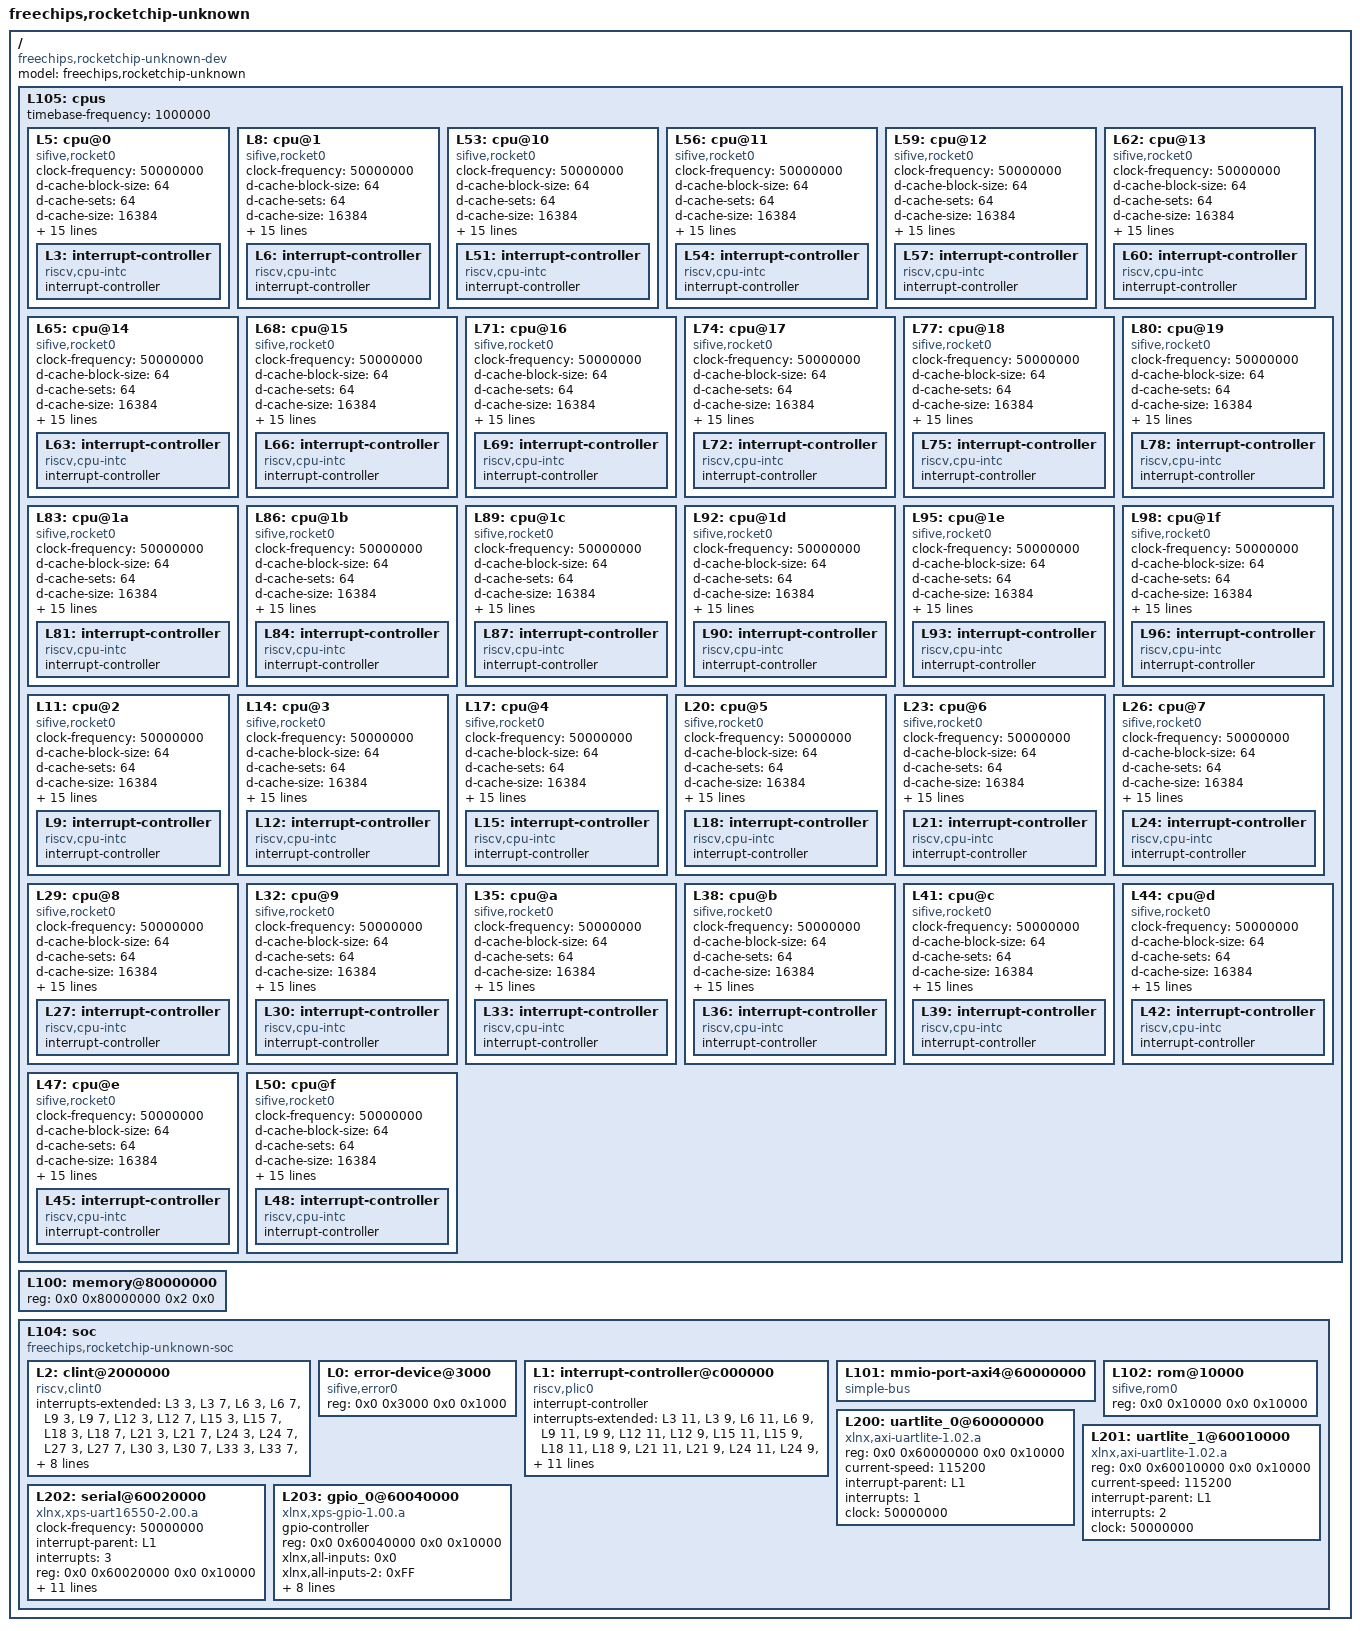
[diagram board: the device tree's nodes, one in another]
/dts-v1/;

/ {
	#address-cells = <2>;
	#size-cells = <2>;
	compatible = "freechips,rocketchip-unknown-dev";
	model = "freechips,rocketchip-unknown";
	L105: cpus {
		#address-cells = <1>;
		#size-cells = <0>;
        timebase-frequency = <1000000>;
		L5: cpu@0 {
			clock-frequency = <50000000>;
			compatible = "sifive,rocket0", "riscv";
			d-cache-block-size = <64>;
			d-cache-sets = <64>;
			d-cache-size = <16384>;
			d-tlb-sets = <1>;
			d-tlb-size = <32>;
			device_type = "cpu";
			hardware-exec-breakpoint-count = <1>;
			i-cache-block-size = <64>;
			i-cache-sets = <64>;
			i-cache-size = <16384>;
			i-tlb-sets = <1>;
			i-tlb-size = <32>;
			mmu-type = "riscv,sv39";
			next-level-cache = <&L100>;
			reg = <0x0>;
			riscv,isa = "rv64imafdc";
			riscv,pmpregions = <8>;
			status = "okay";
			timebase-frequency = <1000000>;
			tlb-split;
			L3: interrupt-controller {
				#interrupt-cells = <1>;
				compatible = "riscv,cpu-intc";
				interrupt-controller;
			};
		};
		L8: cpu@1 {
			clock-frequency = <50000000>;
			compatible = "sifive,rocket0", "riscv";
			d-cache-block-size = <64>;
			d-cache-sets = <64>;
			d-cache-size = <16384>;
			d-tlb-sets = <1>;
			d-tlb-size = <32>;
			device_type = "cpu";
			hardware-exec-breakpoint-count = <1>;
			i-cache-block-size = <64>;
			i-cache-sets = <64>;
			i-cache-size = <16384>;
			i-tlb-sets = <1>;
			i-tlb-size = <32>;
			mmu-type = "riscv,sv39";
			next-level-cache = <&L100>;
			reg = <0x1>;
			riscv,isa = "rv64imafdc";
			riscv,pmpregions = <8>;
			status = "okay";
			timebase-frequency = <1000000>;
			tlb-split;
			L6: interrupt-controller {
				#interrupt-cells = <1>;
				compatible = "riscv,cpu-intc";
				interrupt-controller;
			};
		};
		L53: cpu@10 {
			clock-frequency = <50000000>;
			compatible = "sifive,rocket0", "riscv";
			d-cache-block-size = <64>;
			d-cache-sets = <64>;
			d-cache-size = <16384>;
			d-tlb-sets = <1>;
			d-tlb-size = <32>;
			device_type = "cpu";
			hardware-exec-breakpoint-count = <1>;
			i-cache-block-size = <64>;
			i-cache-sets = <64>;
			i-cache-size = <16384>;
			i-tlb-sets = <1>;
			i-tlb-size = <32>;
			mmu-type = "riscv,sv39";
			next-level-cache = <&L100>;
			reg = <0x10>;
			riscv,isa = "rv64imafdc";
			riscv,pmpregions = <8>;
			status = "okay";
			timebase-frequency = <1000000>;
			tlb-split;
			L51: interrupt-controller {
				#interrupt-cells = <1>;
				compatible = "riscv,cpu-intc";
				interrupt-controller;
			};
		};
		L56: cpu@11 {
			clock-frequency = <50000000>;
			compatible = "sifive,rocket0", "riscv";
			d-cache-block-size = <64>;
			d-cache-sets = <64>;
			d-cache-size = <16384>;
			d-tlb-sets = <1>;
			d-tlb-size = <32>;
			device_type = "cpu";
			hardware-exec-breakpoint-count = <1>;
			i-cache-block-size = <64>;
			i-cache-sets = <64>;
			i-cache-size = <16384>;
			i-tlb-sets = <1>;
			i-tlb-size = <32>;
			mmu-type = "riscv,sv39";
			next-level-cache = <&L100>;
			reg = <0x11>;
			riscv,isa = "rv64imafdc";
			riscv,pmpregions = <8>;
			status = "okay";
			timebase-frequency = <1000000>;
			tlb-split;
			L54: interrupt-controller {
				#interrupt-cells = <1>;
				compatible = "riscv,cpu-intc";
				interrupt-controller;
			};
		};
		L59: cpu@12 {
			clock-frequency = <50000000>;
			compatible = "sifive,rocket0", "riscv";
			d-cache-block-size = <64>;
			d-cache-sets = <64>;
			d-cache-size = <16384>;
			d-tlb-sets = <1>;
			d-tlb-size = <32>;
			device_type = "cpu";
			hardware-exec-breakpoint-count = <1>;
			i-cache-block-size = <64>;
			i-cache-sets = <64>;
			i-cache-size = <16384>;
			i-tlb-sets = <1>;
			i-tlb-size = <32>;
			mmu-type = "riscv,sv39";
			next-level-cache = <&L100>;
			reg = <0x12>;
			riscv,isa = "rv64imafdc";
			riscv,pmpregions = <8>;
			status = "okay";
			timebase-frequency = <1000000>;
			tlb-split;
			L57: interrupt-controller {
				#interrupt-cells = <1>;
				compatible = "riscv,cpu-intc";
				interrupt-controller;
			};
		};
		L62: cpu@13 {
			clock-frequency = <50000000>;
			compatible = "sifive,rocket0", "riscv";
			d-cache-block-size = <64>;
			d-cache-sets = <64>;
			d-cache-size = <16384>;
			d-tlb-sets = <1>;
			d-tlb-size = <32>;
			device_type = "cpu";
			hardware-exec-breakpoint-count = <1>;
			i-cache-block-size = <64>;
			i-cache-sets = <64>;
			i-cache-size = <16384>;
			i-tlb-sets = <1>;
			i-tlb-size = <32>;
			mmu-type = "riscv,sv39";
			next-level-cache = <&L100>;
			reg = <0x13>;
			riscv,isa = "rv64imafdc";
			riscv,pmpregions = <8>;
			status = "okay";
			timebase-frequency = <1000000>;
			tlb-split;
			L60: interrupt-controller {
				#interrupt-cells = <1>;
				compatible = "riscv,cpu-intc";
				interrupt-controller;
			};
		};
		L65: cpu@14 {
			clock-frequency = <50000000>;
			compatible = "sifive,rocket0", "riscv";
			d-cache-block-size = <64>;
			d-cache-sets = <64>;
			d-cache-size = <16384>;
			d-tlb-sets = <1>;
			d-tlb-size = <32>;
			device_type = "cpu";
			hardware-exec-breakpoint-count = <1>;
			i-cache-block-size = <64>;
			i-cache-sets = <64>;
			i-cache-size = <16384>;
			i-tlb-sets = <1>;
			i-tlb-size = <32>;
			mmu-type = "riscv,sv39";
			next-level-cache = <&L100>;
			reg = <0x14>;
			riscv,isa = "rv64imafdc";
			riscv,pmpregions = <8>;
			status = "okay";
			timebase-frequency = <1000000>;
			tlb-split;
			L63: interrupt-controller {
				#interrupt-cells = <1>;
				compatible = "riscv,cpu-intc";
				interrupt-controller;
			};
		};
		L68: cpu@15 {
			clock-frequency = <50000000>;
			compatible = "sifive,rocket0", "riscv";
			d-cache-block-size = <64>;
			d-cache-sets = <64>;
			d-cache-size = <16384>;
			d-tlb-sets = <1>;
			d-tlb-size = <32>;
			device_type = "cpu";
			hardware-exec-breakpoint-count = <1>;
			i-cache-block-size = <64>;
			i-cache-sets = <64>;
			i-cache-size = <16384>;
			i-tlb-sets = <1>;
			i-tlb-size = <32>;
			mmu-type = "riscv,sv39";
			next-level-cache = <&L100>;
			reg = <0x15>;
			riscv,isa = "rv64imafdc";
			riscv,pmpregions = <8>;
			status = "okay";
			timebase-frequency = <1000000>;
			tlb-split;
			L66: interrupt-controller {
				#interrupt-cells = <1>;
				compatible = "riscv,cpu-intc";
				interrupt-controller;
			};
		};
		L71: cpu@16 {
			clock-frequency = <50000000>;
			compatible = "sifive,rocket0", "riscv";
			d-cache-block-size = <64>;
			d-cache-sets = <64>;
			d-cache-size = <16384>;
			d-tlb-sets = <1>;
			d-tlb-size = <32>;
			device_type = "cpu";
			hardware-exec-breakpoint-count = <1>;
			i-cache-block-size = <64>;
			i-cache-sets = <64>;
			i-cache-size = <16384>;
			i-tlb-sets = <1>;
			i-tlb-size = <32>;
			mmu-type = "riscv,sv39";
			next-level-cache = <&L100>;
			reg = <0x16>;
			riscv,isa = "rv64imafdc";
			riscv,pmpregions = <8>;
			status = "okay";
			timebase-frequency = <1000000>;
			tlb-split;
			L69: interrupt-controller {
				#interrupt-cells = <1>;
				compatible = "riscv,cpu-intc";
				interrupt-controller;
			};
		};
		L74: cpu@17 {
			clock-frequency = <50000000>;
			compatible = "sifive,rocket0", "riscv";
			d-cache-block-size = <64>;
			d-cache-sets = <64>;
			d-cache-size = <16384>;
			d-tlb-sets = <1>;
			d-tlb-size = <32>;
			device_type = "cpu";
			hardware-exec-breakpoint-count = <1>;
			i-cache-block-size = <64>;
			i-cache-sets = <64>;
			i-cache-size = <16384>;
			i-tlb-sets = <1>;
			i-tlb-size = <32>;
			mmu-type = "riscv,sv39";
			next-level-cache = <&L100>;
			reg = <0x17>;
			riscv,isa = "rv64imafdc";
			riscv,pmpregions = <8>;
			status = "okay";
			timebase-frequency = <1000000>;
			tlb-split;
			L72: interrupt-controller {
				#interrupt-cells = <1>;
				compatible = "riscv,cpu-intc";
				interrupt-controller;
			};
		};
		L77: cpu@18 {
			clock-frequency = <50000000>;
			compatible = "sifive,rocket0", "riscv";
			d-cache-block-size = <64>;
			d-cache-sets = <64>;
			d-cache-size = <16384>;
			d-tlb-sets = <1>;
			d-tlb-size = <32>;
			device_type = "cpu";
			hardware-exec-breakpoint-count = <1>;
			i-cache-block-size = <64>;
			i-cache-sets = <64>;
			i-cache-size = <16384>;
			i-tlb-sets = <1>;
			i-tlb-size = <32>;
			mmu-type = "riscv,sv39";
			next-level-cache = <&L100>;
			reg = <0x18>;
			riscv,isa = "rv64imafdc";
			riscv,pmpregions = <8>;
			status = "okay";
			timebase-frequency = <1000000>;
			tlb-split;
			L75: interrupt-controller {
				#interrupt-cells = <1>;
				compatible = "riscv,cpu-intc";
				interrupt-controller;
			};
		};
		L80: cpu@19 {
			clock-frequency = <50000000>;
			compatible = "sifive,rocket0", "riscv";
			d-cache-block-size = <64>;
			d-cache-sets = <64>;
			d-cache-size = <16384>;
			d-tlb-sets = <1>;
			d-tlb-size = <32>;
			device_type = "cpu";
			hardware-exec-breakpoint-count = <1>;
			i-cache-block-size = <64>;
			i-cache-sets = <64>;
			i-cache-size = <16384>;
			i-tlb-sets = <1>;
			i-tlb-size = <32>;
			mmu-type = "riscv,sv39";
			next-level-cache = <&L100>;
			reg = <0x19>;
			riscv,isa = "rv64imafdc";
			riscv,pmpregions = <8>;
			status = "okay";
			timebase-frequency = <1000000>;
			tlb-split;
			L78: interrupt-controller {
				#interrupt-cells = <1>;
				compatible = "riscv,cpu-intc";
				interrupt-controller;
			};
		};
		L83: cpu@1a {
			clock-frequency = <50000000>;
			compatible = "sifive,rocket0", "riscv";
			d-cache-block-size = <64>;
			d-cache-sets = <64>;
			d-cache-size = <16384>;
			d-tlb-sets = <1>;
			d-tlb-size = <32>;
			device_type = "cpu";
			hardware-exec-breakpoint-count = <1>;
			i-cache-block-size = <64>;
			i-cache-sets = <64>;
			i-cache-size = <16384>;
			i-tlb-sets = <1>;
			i-tlb-size = <32>;
			mmu-type = "riscv,sv39";
			next-level-cache = <&L100>;
			reg = <0x1a>;
			riscv,isa = "rv64imafdc";
			riscv,pmpregions = <8>;
			status = "okay";
			timebase-frequency = <1000000>;
			tlb-split;
			L81: interrupt-controller {
				#interrupt-cells = <1>;
				compatible = "riscv,cpu-intc";
				interrupt-controller;
			};
		};
		L86: cpu@1b {
			clock-frequency = <50000000>;
			compatible = "sifive,rocket0", "riscv";
			d-cache-block-size = <64>;
			d-cache-sets = <64>;
			d-cache-size = <16384>;
			d-tlb-sets = <1>;
			d-tlb-size = <32>;
			device_type = "cpu";
			hardware-exec-breakpoint-count = <1>;
			i-cache-block-size = <64>;
			i-cache-sets = <64>;
			i-cache-size = <16384>;
			i-tlb-sets = <1>;
			i-tlb-size = <32>;
			mmu-type = "riscv,sv39";
			next-level-cache = <&L100>;
			reg = <0x1b>;
			riscv,isa = "rv64imafdc";
			riscv,pmpregions = <8>;
			status = "okay";
			timebase-frequency = <1000000>;
			tlb-split;
			L84: interrupt-controller {
				#interrupt-cells = <1>;
				compatible = "riscv,cpu-intc";
				interrupt-controller;
			};
		};
		L89: cpu@1c {
			clock-frequency = <50000000>;
			compatible = "sifive,rocket0", "riscv";
			d-cache-block-size = <64>;
			d-cache-sets = <64>;
			d-cache-size = <16384>;
			d-tlb-sets = <1>;
			d-tlb-size = <32>;
			device_type = "cpu";
			hardware-exec-breakpoint-count = <1>;
			i-cache-block-size = <64>;
			i-cache-sets = <64>;
			i-cache-size = <16384>;
			i-tlb-sets = <1>;
			i-tlb-size = <32>;
			mmu-type = "riscv,sv39";
			next-level-cache = <&L100>;
			reg = <0x1c>;
			riscv,isa = "rv64imafdc";
			riscv,pmpregions = <8>;
			status = "okay";
			timebase-frequency = <1000000>;
			tlb-split;
			L87: interrupt-controller {
				#interrupt-cells = <1>;
				compatible = "riscv,cpu-intc";
				interrupt-controller;
			};
		};
		L92: cpu@1d {
			clock-frequency = <50000000>;
			compatible = "sifive,rocket0", "riscv";
			d-cache-block-size = <64>;
			d-cache-sets = <64>;
			d-cache-size = <16384>;
			d-tlb-sets = <1>;
			d-tlb-size = <32>;
			device_type = "cpu";
			hardware-exec-breakpoint-count = <1>;
			i-cache-block-size = <64>;
			i-cache-sets = <64>;
			i-cache-size = <16384>;
			i-tlb-sets = <1>;
			i-tlb-size = <32>;
			mmu-type = "riscv,sv39";
			next-level-cache = <&L100>;
			reg = <0x1d>;
			riscv,isa = "rv64imafdc";
			riscv,pmpregions = <8>;
			status = "okay";
			timebase-frequency = <1000000>;
			tlb-split;
			L90: interrupt-controller {
				#interrupt-cells = <1>;
				compatible = "riscv,cpu-intc";
				interrupt-controller;
			};
		};
		L95: cpu@1e {
			clock-frequency = <50000000>;
			compatible = "sifive,rocket0", "riscv";
			d-cache-block-size = <64>;
			d-cache-sets = <64>;
			d-cache-size = <16384>;
			d-tlb-sets = <1>;
			d-tlb-size = <32>;
			device_type = "cpu";
			hardware-exec-breakpoint-count = <1>;
			i-cache-block-size = <64>;
			i-cache-sets = <64>;
			i-cache-size = <16384>;
			i-tlb-sets = <1>;
			i-tlb-size = <32>;
			mmu-type = "riscv,sv39";
			next-level-cache = <&L100>;
			reg = <0x1e>;
			riscv,isa = "rv64imafdc";
			riscv,pmpregions = <8>;
			status = "okay";
			timebase-frequency = <1000000>;
			tlb-split;
			L93: interrupt-controller {
				#interrupt-cells = <1>;
				compatible = "riscv,cpu-intc";
				interrupt-controller;
			};
		};
		L98: cpu@1f {
			clock-frequency = <50000000>;
			compatible = "sifive,rocket0", "riscv";
			d-cache-block-size = <64>;
			d-cache-sets = <64>;
			d-cache-size = <16384>;
			d-tlb-sets = <1>;
			d-tlb-size = <32>;
			device_type = "cpu";
			hardware-exec-breakpoint-count = <1>;
			i-cache-block-size = <64>;
			i-cache-sets = <64>;
			i-cache-size = <16384>;
			i-tlb-sets = <1>;
			i-tlb-size = <32>;
			mmu-type = "riscv,sv39";
			next-level-cache = <&L100>;
			reg = <0x1f>;
			riscv,isa = "rv64imafdc";
			riscv,pmpregions = <8>;
			status = "okay";
			timebase-frequency = <1000000>;
			tlb-split;
			L96: interrupt-controller {
				#interrupt-cells = <1>;
				compatible = "riscv,cpu-intc";
				interrupt-controller;
			};
		};
		L11: cpu@2 {
			clock-frequency = <50000000>;
			compatible = "sifive,rocket0", "riscv";
			d-cache-block-size = <64>;
			d-cache-sets = <64>;
			d-cache-size = <16384>;
			d-tlb-sets = <1>;
			d-tlb-size = <32>;
			device_type = "cpu";
			hardware-exec-breakpoint-count = <1>;
			i-cache-block-size = <64>;
			i-cache-sets = <64>;
			i-cache-size = <16384>;
			i-tlb-sets = <1>;
			i-tlb-size = <32>;
			mmu-type = "riscv,sv39";
			next-level-cache = <&L100>;
			reg = <0x2>;
			riscv,isa = "rv64imafdc";
			riscv,pmpregions = <8>;
			status = "okay";
			timebase-frequency = <1000000>;
			tlb-split;
			L9: interrupt-controller {
				#interrupt-cells = <1>;
				compatible = "riscv,cpu-intc";
				interrupt-controller;
			};
		};
		L14: cpu@3 {
			clock-frequency = <50000000>;
			compatible = "sifive,rocket0", "riscv";
			d-cache-block-size = <64>;
			d-cache-sets = <64>;
			d-cache-size = <16384>;
			d-tlb-sets = <1>;
			d-tlb-size = <32>;
			device_type = "cpu";
			hardware-exec-breakpoint-count = <1>;
			i-cache-block-size = <64>;
			i-cache-sets = <64>;
			i-cache-size = <16384>;
			i-tlb-sets = <1>;
			i-tlb-size = <32>;
			mmu-type = "riscv,sv39";
			next-level-cache = <&L100>;
			reg = <0x3>;
			riscv,isa = "rv64imafdc";
			riscv,pmpregions = <8>;
			status = "okay";
			timebase-frequency = <1000000>;
			tlb-split;
			L12: interrupt-controller {
				#interrupt-cells = <1>;
				compatible = "riscv,cpu-intc";
				interrupt-controller;
			};
		};
		L17: cpu@4 {
			clock-frequency = <50000000>;
			compatible = "sifive,rocket0", "riscv";
			d-cache-block-size = <64>;
			d-cache-sets = <64>;
			d-cache-size = <16384>;
			d-tlb-sets = <1>;
			d-tlb-size = <32>;
			device_type = "cpu";
			hardware-exec-breakpoint-count = <1>;
			i-cache-block-size = <64>;
			i-cache-sets = <64>;
			i-cache-size = <16384>;
			i-tlb-sets = <1>;
			i-tlb-size = <32>;
			mmu-type = "riscv,sv39";
			next-level-cache = <&L100>;
			reg = <0x4>;
			riscv,isa = "rv64imafdc";
			riscv,pmpregions = <8>;
			status = "okay";
			timebase-frequency = <1000000>;
			tlb-split;
			L15: interrupt-controller {
				#interrupt-cells = <1>;
				compatible = "riscv,cpu-intc";
				interrupt-controller;
			};
		};
		L20: cpu@5 {
			clock-frequency = <50000000>;
			compatible = "sifive,rocket0", "riscv";
			d-cache-block-size = <64>;
			d-cache-sets = <64>;
			d-cache-size = <16384>;
			d-tlb-sets = <1>;
			d-tlb-size = <32>;
			device_type = "cpu";
			hardware-exec-breakpoint-count = <1>;
			i-cache-block-size = <64>;
			i-cache-sets = <64>;
			i-cache-size = <16384>;
			i-tlb-sets = <1>;
			i-tlb-size = <32>;
			mmu-type = "riscv,sv39";
			next-level-cache = <&L100>;
			reg = <0x5>;
			riscv,isa = "rv64imafdc";
			riscv,pmpregions = <8>;
			status = "okay";
			timebase-frequency = <1000000>;
			tlb-split;
			L18: interrupt-controller {
				#interrupt-cells = <1>;
				compatible = "riscv,cpu-intc";
				interrupt-controller;
			};
		};
		L23: cpu@6 {
			clock-frequency = <50000000>;
			compatible = "sifive,rocket0", "riscv";
			d-cache-block-size = <64>;
			d-cache-sets = <64>;
			d-cache-size = <16384>;
			d-tlb-sets = <1>;
			d-tlb-size = <32>;
			device_type = "cpu";
			hardware-exec-breakpoint-count = <1>;
			i-cache-block-size = <64>;
			i-cache-sets = <64>;
			i-cache-size = <16384>;
			i-tlb-sets = <1>;
			i-tlb-size = <32>;
			mmu-type = "riscv,sv39";
			next-level-cache = <&L100>;
			reg = <0x6>;
			riscv,isa = "rv64imafdc";
			riscv,pmpregions = <8>;
			status = "okay";
			timebase-frequency = <1000000>;
			tlb-split;
			L21: interrupt-controller {
				#interrupt-cells = <1>;
				compatible = "riscv,cpu-intc";
				interrupt-controller;
			};
		};
		L26: cpu@7 {
			clock-frequency = <50000000>;
			compatible = "sifive,rocket0", "riscv";
			d-cache-block-size = <64>;
			d-cache-sets = <64>;
			d-cache-size = <16384>;
			d-tlb-sets = <1>;
			d-tlb-size = <32>;
			device_type = "cpu";
			hardware-exec-breakpoint-count = <1>;
			i-cache-block-size = <64>;
			i-cache-sets = <64>;
			i-cache-size = <16384>;
			i-tlb-sets = <1>;
			i-tlb-size = <32>;
			mmu-type = "riscv,sv39";
			next-level-cache = <&L100>;
			reg = <0x7>;
			riscv,isa = "rv64imafdc";
			riscv,pmpregions = <8>;
			status = "okay";
			timebase-frequency = <1000000>;
			tlb-split;
			L24: interrupt-controller {
				#interrupt-cells = <1>;
				compatible = "riscv,cpu-intc";
				interrupt-controller;
			};
		};
		L29: cpu@8 {
			clock-frequency = <50000000>;
			compatible = "sifive,rocket0", "riscv";
			d-cache-block-size = <64>;
			d-cache-sets = <64>;
			d-cache-size = <16384>;
			d-tlb-sets = <1>;
			d-tlb-size = <32>;
			device_type = "cpu";
			hardware-exec-breakpoint-count = <1>;
			i-cache-block-size = <64>;
			i-cache-sets = <64>;
			i-cache-size = <16384>;
			i-tlb-sets = <1>;
			i-tlb-size = <32>;
			mmu-type = "riscv,sv39";
			next-level-cache = <&L100>;
			reg = <0x8>;
			riscv,isa = "rv64imafdc";
			riscv,pmpregions = <8>;
			status = "okay";
			timebase-frequency = <1000000>;
			tlb-split;
			L27: interrupt-controller {
				#interrupt-cells = <1>;
				compatible = "riscv,cpu-intc";
				interrupt-controller;
			};
		};
		L32: cpu@9 {
			clock-frequency = <50000000>;
			compatible = "sifive,rocket0", "riscv";
			d-cache-block-size = <64>;
			d-cache-sets = <64>;
			d-cache-size = <16384>;
			d-tlb-sets = <1>;
			d-tlb-size = <32>;
			device_type = "cpu";
			hardware-exec-breakpoint-count = <1>;
			i-cache-block-size = <64>;
			i-cache-sets = <64>;
			i-cache-size = <16384>;
			i-tlb-sets = <1>;
			i-tlb-size = <32>;
			mmu-type = "riscv,sv39";
			next-level-cache = <&L100>;
			reg = <0x9>;
			riscv,isa = "rv64imafdc";
			riscv,pmpregions = <8>;
			status = "okay";
			timebase-frequency = <1000000>;
			tlb-split;
			L30: interrupt-controller {
				#interrupt-cells = <1>;
				compatible = "riscv,cpu-intc";
				interrupt-controller;
			};
		};
		L35: cpu@a {
			clock-frequency = <50000000>;
			compatible = "sifive,rocket0", "riscv";
			d-cache-block-size = <64>;
			d-cache-sets = <64>;
			d-cache-size = <16384>;
			d-tlb-sets = <1>;
			d-tlb-size = <32>;
			device_type = "cpu";
			hardware-exec-breakpoint-count = <1>;
			i-cache-block-size = <64>;
			i-cache-sets = <64>;
			i-cache-size = <16384>;
			i-tlb-sets = <1>;
			i-tlb-size = <32>;
			mmu-type = "riscv,sv39";
			next-level-cache = <&L100>;
			reg = <0xa>;
			riscv,isa = "rv64imafdc";
			riscv,pmpregions = <8>;
			status = "okay";
			timebase-frequency = <1000000>;
			tlb-split;
			L33: interrupt-controller {
				#interrupt-cells = <1>;
				compatible = "riscv,cpu-intc";
				interrupt-controller;
			};
		};
		L38: cpu@b {
			clock-frequency = <50000000>;
			compatible = "sifive,rocket0", "riscv";
			d-cache-block-size = <64>;
			d-cache-sets = <64>;
			d-cache-size = <16384>;
			d-tlb-sets = <1>;
			d-tlb-size = <32>;
			device_type = "cpu";
			hardware-exec-breakpoint-count = <1>;
			i-cache-block-size = <64>;
			i-cache-sets = <64>;
			i-cache-size = <16384>;
			i-tlb-sets = <1>;
			i-tlb-size = <32>;
			mmu-type = "riscv,sv39";
			next-level-cache = <&L100>;
			reg = <0xb>;
			riscv,isa = "rv64imafdc";
			riscv,pmpregions = <8>;
			status = "okay";
			timebase-frequency = <1000000>;
			tlb-split;
			L36: interrupt-controller {
				#interrupt-cells = <1>;
				compatible = "riscv,cpu-intc";
				interrupt-controller;
			};
		};
		L41: cpu@c {
			clock-frequency = <50000000>;
			compatible = "sifive,rocket0", "riscv";
			d-cache-block-size = <64>;
			d-cache-sets = <64>;
			d-cache-size = <16384>;
			d-tlb-sets = <1>;
			d-tlb-size = <32>;
			device_type = "cpu";
			hardware-exec-breakpoint-count = <1>;
			i-cache-block-size = <64>;
			i-cache-sets = <64>;
			i-cache-size = <16384>;
			i-tlb-sets = <1>;
			i-tlb-size = <32>;
			mmu-type = "riscv,sv39";
			next-level-cache = <&L100>;
			reg = <0xc>;
			riscv,isa = "rv64imafdc";
			riscv,pmpregions = <8>;
			status = "okay";
			timebase-frequency = <1000000>;
			tlb-split;
			L39: interrupt-controller {
				#interrupt-cells = <1>;
				compatible = "riscv,cpu-intc";
				interrupt-controller;
			};
		};
		L44: cpu@d {
			clock-frequency = <50000000>;
			compatible = "sifive,rocket0", "riscv";
			d-cache-block-size = <64>;
			d-cache-sets = <64>;
			d-cache-size = <16384>;
			d-tlb-sets = <1>;
			d-tlb-size = <32>;
			device_type = "cpu";
			hardware-exec-breakpoint-count = <1>;
			i-cache-block-size = <64>;
			i-cache-sets = <64>;
			i-cache-size = <16384>;
			i-tlb-sets = <1>;
			i-tlb-size = <32>;
			mmu-type = "riscv,sv39";
			next-level-cache = <&L100>;
			reg = <0xd>;
			riscv,isa = "rv64imafdc";
			riscv,pmpregions = <8>;
			status = "okay";
			timebase-frequency = <1000000>;
			tlb-split;
			L42: interrupt-controller {
				#interrupt-cells = <1>;
				compatible = "riscv,cpu-intc";
				interrupt-controller;
			};
		};
		L47: cpu@e {
			clock-frequency = <50000000>;
			compatible = "sifive,rocket0", "riscv";
			d-cache-block-size = <64>;
			d-cache-sets = <64>;
			d-cache-size = <16384>;
			d-tlb-sets = <1>;
			d-tlb-size = <32>;
			device_type = "cpu";
			hardware-exec-breakpoint-count = <1>;
			i-cache-block-size = <64>;
			i-cache-sets = <64>;
			i-cache-size = <16384>;
			i-tlb-sets = <1>;
			i-tlb-size = <32>;
			mmu-type = "riscv,sv39";
			next-level-cache = <&L100>;
			reg = <0xe>;
			riscv,isa = "rv64imafdc";
			riscv,pmpregions = <8>;
			status = "okay";
			timebase-frequency = <1000000>;
			tlb-split;
			L45: interrupt-controller {
				#interrupt-cells = <1>;
				compatible = "riscv,cpu-intc";
				interrupt-controller;
			};
		};
		L50: cpu@f {
			clock-frequency = <50000000>;
			compatible = "sifive,rocket0", "riscv";
			d-cache-block-size = <64>;
			d-cache-sets = <64>;
			d-cache-size = <16384>;
			d-tlb-sets = <1>;
			d-tlb-size = <32>;
			device_type = "cpu";
			hardware-exec-breakpoint-count = <1>;
			i-cache-block-size = <64>;
			i-cache-sets = <64>;
			i-cache-size = <16384>;
			i-tlb-sets = <1>;
			i-tlb-size = <32>;
			mmu-type = "riscv,sv39";
			next-level-cache = <&L100>;
			reg = <0xf>;
			riscv,isa = "rv64imafdc";
			riscv,pmpregions = <8>;
			status = "okay";
			timebase-frequency = <1000000>;
			tlb-split;
			L48: interrupt-controller {
				#interrupt-cells = <1>;
				compatible = "riscv,cpu-intc";
				interrupt-controller;
			};
		};
	};
	L100: memory@80000000 {
		device_type = "memory";
		reg = <0x0 0x80000000 0x2 0x0>;
	};
	L104: soc {
		#address-cells = <2>;
		#size-cells = <2>;
		compatible = "freechips,rocketchip-unknown-soc", "simple-bus";
		ranges;
		L2: clint@2000000 {
			compatible = "riscv,clint0";
			interrupts-extended = <&L3 3 &L3 7 &L6 3 &L6 7 &L9 3 &L9 7 &L12 3 &L12 7 &L15 3 &L15 7 &L18 3 &L18 7 &L21 3 &L21 7 &L24 3 &L24 7 &L27 3 &L27 7 &L30 3 &L30 7 &L33 3 &L33 7 &L36 3 &L36 7 &L39 3 &L39 7 &L42 3 &L42 7 &L45 3 &L45 7 &L48 3 &L48 7 &L51 3 &L51 7 &L54 3 &L54 7 &L57 3 &L57 7 &L60 3 &L60 7 &L63 3 &L63 7 &L66 3 &L66 7 &L69 3 &L69 7 &L72 3 &L72 7 &L75 3 &L75 7 &L78 3 &L78 7 &L81 3 &L81 7 &L84 3 &L84 7 &L87 3 &L87 7 &L90 3 &L90 7 &L93 3 &L93 7 &L96 3 &L96 7>;
			reg = <0x0 0x2000000 0x0 0x10000>;
			reg-names = "control";
		};
		L0: error-device@3000 {
			compatible = "sifive,error0";
			reg = <0x0 0x3000 0x0 0x1000>;
		};
		L1: interrupt-controller@c000000 {
			#interrupt-cells = <1>;
			compatible = "riscv,plic0";
			interrupt-controller;
			interrupts-extended = <&L3 11 &L3 9 &L6 11 &L6 9 &L9 11 &L9 9 &L12 11 &L12 9 &L15 11 &L15 9 &L18 11 &L18 9 &L21 11 &L21 9 &L24 11 &L24 9 &L27 11 &L27 9 &L30 11 &L30 9 &L33 11 &L33 9 &L36 11 &L36 9 &L39 11 &L39 9 &L42 11 &L42 9 &L45 11 &L45 9 &L48 11 &L48 9 &L51 11 &L51 9 &L54 11 &L54 9 &L57 11 &L57 9 &L60 11 &L60 9 &L63 11 &L63 9 &L66 11 &L66 9 &L69 11 &L69 9 &L72 11 &L72 9 &L75 11 &L75 9 &L78 11 &L78 9 &L81 11 &L81 9 &L84 11 &L84 9 &L87 11 &L87 9 &L90 11 &L90 9 &L93 11 &L93 9 &L96 11 &L96 9>;
			reg = <0x0 0xc000000 0x0 0x4000000>;
			reg-names = "control";
			riscv,max-priority = <3>;
			riscv,ndev = <3>;
		};
		L101: mmio-port-axi4@60000000 {
			#address-cells = <1>;
			#size-cells = <1>;
			compatible = "simple-bus";
			ranges = <0x60000000 0x0 0x60000000 0x20000000>;
		};
		L102: rom@10000 {
			compatible = "sifive,rom0";
			reg = <0x0 0x10000 0x0 0x10000>;
			reg-names = "mem";
		};
        L200: uartlite_0@60000000 {
            compatible = "xlnx,axi-uartlite-1.02.a", "xlnx,xps-uartlite-1.00.a";
            reg = <0x0 0x60000000 0x0 0x10000>;
            current-speed = <115200>;
            device_type = "serial";
            interrupt-parent = <&L1>;
            interrupts = <1>;
            clock = <50000000>;
        };
        L201: uartlite_1@60010000 {
            compatible = "xlnx,axi-uartlite-1.02.a", "xlnx,xps-uartlite-1.00.a";
            reg = <0x0 0x60010000 0x0 0x10000>;
            current-speed = <115200>;
            device_type = "serial";
            interrupt-parent = <&L1>;
            interrupts = <2>;
            clock = <50000000>;
        };
        L202: serial@60020000 {
            clock-frequency = <50000000>;
            compatible = "xlnx,xps-uart16550-2.00.a", "ns16550a";
            device_type = "serial";
            interrupt-parent = <&L1>;
            interrupts = <3>;
            reg = <0x0 0x60020000 0x0 0x10000>;
            reg-offset = <0x1000>;
            reg-shift = <2>;
            current-speed = <115200>;
            xlnx,external-xin-clk-hz = <50000000>;
            xlnx,family = "zynq";
            xlnx,has-external-rclk = <0x0>;
            xlnx,has-external-xin = <0x0>;
            xlnx,is-a-16550 = <0x1>;
            XLNx,s-axi-aclk-freq-hz = <50000000>;
            xlnx,use-modem-ports = <0x0>;
            xlnx,use-user-ports = <0x0>;
        };
        L203: gpio_0@60040000 {
            #gpio-cells = <2>;
            compatible = "xlnx,xps-gpio-1.00.a";
            gpio-controller;
            reg = <0x0 0x60040000 0x0 0x10000>;
            xlnx,all-inputs = <0x0>;
            xlnx,all-inputs-2 = <0xFF>;
            xlnx,dout-default = <0x0>;
            xlnx,dout-default-2 = <0x0>;
            xlnx,gpio-width = <0x8>;
            xlnx,gpio2-width = <0x8>;
            xlnx,interrupt-present = <0x0>;
            xlnx,is-dual = <0x1>;
            xlnx,tri-default = <0x00000000>;
            xlnx,tri-default-2 = <0xffffffff>;
        };
	};
};
